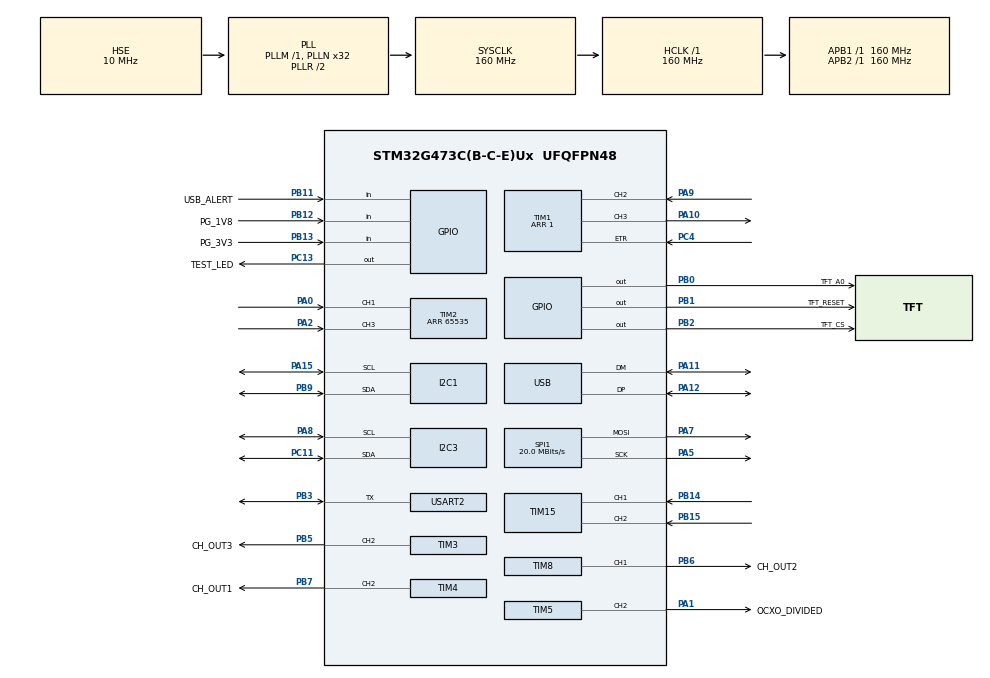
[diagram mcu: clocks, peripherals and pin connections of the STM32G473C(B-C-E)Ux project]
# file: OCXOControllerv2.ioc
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Dma.I2C3_RX.3.Direction=DMA_PERIPH_TO_MEMORY
Dma.I2C3_RX.3.EventEnable=DISABLE
Dma.I2C3_RX.3.Instance=DMA2_Channel1
Dma.I2C3_RX.3.MemDataAlignment=DMA_MDATAALIGN_BYTE
Dma.I2C3_RX.3.MemInc=DMA_MINC_ENABLE
Dma.I2C3_RX.3.Mode=DMA_NORMAL
Dma.I2C3_RX.3.PeriphDataAlignment=DMA_PDATAALIGN_BYTE
Dma.I2C3_RX.3.PeriphInc=DMA_PINC_DISABLE
Dma.I2C3_RX.3.Polarity=HAL_DMAMUX_REQ_GEN_RISING
Dma.I2C3_RX.3.Priority=DMA_PRIORITY_LOW
Dma.I2C3_RX.3.RequestNumber=1
Dma.I2C3_RX.3.SignalID=NONE
Dma.I2C3_RX.3.SyncEnable=DISABLE
Dma.I2C3_RX.3.SyncPolarity=HAL_DMAMUX_SYNC_NO_EVENT
Dma.I2C3_RX.3.SyncRequestNumber=1
Dma.I2C3_RX.3.SyncSignalID=NONE
Dma.I2C3_TX.4.Direction=DMA_MEMORY_TO_PERIPH
Dma.I2C3_TX.4.EventEnable=DISABLE
Dma.I2C3_TX.4.Instance=DMA2_Channel2
Dma.I2C3_TX.4.MemDataAlignment=DMA_MDATAALIGN_BYTE
Dma.I2C3_TX.4.MemInc=DMA_MINC_ENABLE
Dma.I2C3_TX.4.Mode=DMA_NORMAL
Dma.I2C3_TX.4.PeriphDataAlignment=DMA_PDATAALIGN_BYTE
Dma.I2C3_TX.4.PeriphInc=DMA_PINC_DISABLE
Dma.I2C3_TX.4.Polarity=HAL_DMAMUX_REQ_GEN_RISING
Dma.I2C3_TX.4.Priority=DMA_PRIORITY_LOW
Dma.I2C3_TX.4.RequestNumber=1
Dma.I2C3_TX.4.SignalID=NONE
Dma.I2C3_TX.4.SyncEnable=DISABLE
Dma.I2C3_TX.4.SyncPolarity=HAL_DMAMUX_SYNC_NO_EVENT
Dma.I2C3_TX.4.SyncRequestNumber=1
Dma.I2C3_TX.4.SyncSignalID=NONE
Dma.Request0=USART2_RX
Dma.Request1=USART2_TX
Dma.Request2=SPI1_TX
Dma.Request3=I2C3_RX
Dma.Request4=I2C3_TX
Dma.SPI1_TX.2.Direction=DMA_MEMORY_TO_PERIPH
Dma.SPI1_TX.2.EventEnable=DISABLE
Dma.SPI1_TX.2.Instance=DMA1_Channel3
Dma.SPI1_TX.2.MemDataAlignment=DMA_MDATAALIGN_BYTE
Dma.SPI1_TX.2.MemInc=DMA_MINC_ENABLE
Dma.SPI1_TX.2.Mode=DMA_NORMAL
Dma.SPI1_TX.2.PeriphDataAlignment=DMA_PDATAALIGN_BYTE
Dma.SPI1_TX.2.PeriphInc=DMA_PINC_DISABLE
Dma.SPI1_TX.2.Polarity=HAL_DMAMUX_REQ_GEN_RISING
Dma.SPI1_TX.2.Priority=DMA_PRIORITY_VERY_HIGH
Dma.SPI1_TX.2.RequestNumber=1
Dma.SPI1_TX.2.SignalID=NONE
Dma.SPI1_TX.2.SyncEnable=DISABLE
Dma.SPI1_TX.2.SyncPolarity=HAL_DMAMUX_SYNC_NO_EVENT
Dma.SPI1_TX.2.SyncRequestNumber=1
Dma.SPI1_TX.2.SyncSignalID=NONE
Dma.USART2_RX.0.Direction=DMA_PERIPH_TO_MEMORY
Dma.USART2_RX.0.EventEnable=DISABLE
Dma.USART2_RX.0.Instance=DMA1_Channel1
Dma.USART2_RX.0.MemDataAlignment=DMA_MDATAALIGN_BYTE
Dma.USART2_RX.0.MemInc=DMA_MINC_ENABLE
Dma.USART2_RX.0.Mode=DMA_NORMAL
Dma.USART2_RX.0.PeriphDataAlignment=DMA_PDATAALIGN_BYTE
Dma.USART2_RX.0.PeriphInc=DMA_PINC_DISABLE
Dma.USART2_RX.0.Polarity=HAL_DMAMUX_REQ_GEN_RISING
Dma.USART2_RX.0.Priority=DMA_PRIORITY_LOW
Dma.USART2_RX.0.RequestNumber=1
Dma.USART2_RX.0.SignalID=NONE
Dma.USART2_RX.0.SyncEnable=DISABLE
Dma.USART2_RX.0.SyncPolarity=HAL_DMAMUX_SYNC_NO_EVENT
Dma.USART2_RX.0.SyncRequestNumber=1
Dma.USART2_RX.0.SyncSignalID=NONE
Dma.USART2_TX.1.Direction=DMA_MEMORY_TO_PERIPH
Dma.USART2_TX.1.EventEnable=DISABLE
Dma.USART2_TX.1.Instance=DMA1_Channel4
Dma.USART2_TX.1.MemDataAlignment=DMA_MDATAALIGN_BYTE
Dma.USART2_TX.1.MemInc=DMA_MINC_ENABLE
Dma.USART2_TX.1.Mode=DMA_NORMAL
Dma.USART2_TX.1.PeriphDataAlignment=DMA_PDATAALIGN_BYTE
Dma.USART2_TX.1.PeriphInc=DMA_PINC_DISABLE
Dma.USART2_TX.1.Polarity=HAL_DMAMUX_REQ_GEN_RISING
Dma.USART2_TX.1.Priority=DMA_PRIORITY_LOW
Dma.USART2_TX.1.RequestNumber=1
Dma.USART2_TX.1.SignalID=NONE
Dma.USART2_TX.1.SyncEnable=DISABLE
Dma.USART2_TX.1.SyncPolarity=HAL_DMAMUX_SYNC_NO_EVENT
Dma.USART2_TX.1.SyncRequestNumber=1
Dma.USART2_TX.1.SyncSignalID=NONE
I2C1.Speed=100
I2C1.Timing=0x30D29DE4
I2C3.Timing=0x30D29DE4
Mcu.Family=STM32G4
Mcu.Name=STM32G473C(B-C-E)Ux
Mcu.Package=UFQFPN48
NVIC.DMA1_Channel1_IRQn=true\:0\:0\:false\:false\:true\:false\:true\:true
NVIC.DMA1_Channel3_IRQn=true\:0\:0\:false\:false\:true\:false\:true\:true
NVIC.DMA1_Channel4_IRQn=true\:0\:0\:false\:false\:true\:false\:true\:true
NVIC.DMA2_Channel1_IRQn=true\:0\:0\:false\:false\:true\:false\:true\:true
NVIC.DMA2_Channel2_IRQn=true\:0\:0\:false\:false\:true\:false\:true\:true
NVIC.PriorityGroup=NVIC_PRIORITYGROUP_4
NVIC.TIM1_BRK_TIM15_IRQn=true\:0\:0\:false\:false\:true\:true\:true\:true
NVIC.TIM2_IRQn=true\:0\:0\:false\:false\:true\:true\:true\:true
NVIC.TIM6_DAC_IRQn=true\:0\:0\:true\:false\:true\:true\:true\:true
NVIC.TIM7_DAC_IRQn=true\:2\:0\:true\:false\:true\:true\:true\:true
NVIC.USB_LP_IRQn=true\:0\:0\:false\:false\:true\:false\:true\:true
PA0.Signal=S_TIM2_CH1
PA1.GPIO_Label=OCXO_DIVIDED
PA1.GPIO_Speed=GPIO_SPEED_FREQ_VERY_HIGH
PA1.Signal=S_TIM5_CH2
PA10.Signal=S_TIM1_CH3
PA11.Mode=Device
PA11.Signal=USB_DM
PA12.Mode=Device
PA12.Signal=USB_DP
PA13.Mode=Serial_Wire
PA13.Signal=SYS_JTMS-SWDIO
PA14.Mode=Serial_Wire
PA14.Signal=SYS_JTCK-SWCLK
PA15.Mode=I2C
PA15.Signal=I2C1_SCL
PA2.Signal=S_TIM2_CH3
PA5.GPIO_Speed=GPIO_SPEED_FREQ_VERY_HIGH
PA5.Mode=TX_Only_Simplex_Unidirect_Master
PA5.Signal=SPI1_SCK
PA7.GPIO_Speed=GPIO_SPEED_FREQ_VERY_HIGH
PA7.Mode=TX_Only_Simplex_Unidirect_Master
PA7.Signal=SPI1_MOSI
PA8.Mode=I2C
PA8.Signal=I2C3_SCL
PA9.Signal=S_TIM1_CH2
PB0.GPIO_Label=TFT_A0
PB0.Signal=GPIO_Output
PB1.GPIO_Label=TFT_RESET
PB1.Signal=GPIO_Output
PB11.GPIO_Label=USB_ALERT
PB11.Signal=GPIO_Input
PB12.GPIO_Label=PG_1V8
PB12.Signal=GPIO_Input
PB13.GPIO_Label=PG_3V3
PB13.Signal=GPIO_Input
PB14.Signal=S_TIM15_CH1
PB15.Signal=S_TIM15_CH2
PB2.GPIO_Label=TFT_CS
PB2.Signal=GPIO_Output
PB3.Mode=Half_duplex(single_wire_mode)
PB3.Signal=USART2_TX
PB5.GPIO_Label=CH_OUT3
PB5.GPIO_Speed=GPIO_SPEED_FREQ_VERY_HIGH
PB5.Signal=S_TIM3_CH2
PB6.GPIO_Label=CH_OUT2
PB6.GPIO_Speed=GPIO_SPEED_FREQ_VERY_HIGH
PB6.Signal=S_TIM8_CH1
PB7.GPIO_Label=CH_OUT1
PB7.GPIO_Speed=GPIO_SPEED_FREQ_VERY_HIGH
PB7.Signal=S_TIM4_CH2
PB9.Mode=I2C
PB9.Signal=I2C1_SDA
PC11.Mode=I2C
PC11.Signal=I2C3_SDA
PC13.GPIO_Label=TEST_LED
PC13.PinState=GPIO_PIN_RESET
PC13.Signal=GPIO_Output
PC4.Signal=S_TIM1_ETR
PF0-OSC_IN.Mode=HSE-External-Clock-Source
PF0-OSC_IN.Signal=RCC_OSC_IN
ProjectManager.HeapSize=0x200
ProjectManager.StackSize=0x400
ProjectManager.TargetToolchain=STM32CubeIDE
RCC.ADC12Freq_Value=160000000
RCC.ADC345Freq_Value=160000000
RCC.AHBFreq_Value=160000000
RCC.APB1Freq_Value=160000000
RCC.APB1TimFreq_Value=160000000
RCC.APB2Freq_Value=160000000
RCC.APB2TimFreq_Value=160000000
RCC.CK48CLockSelection=RCC_USBCLKSOURCE_HSI48
RCC.CortexFreq_Value=160000000
RCC.EXTERNAL_CLOCK_VALUE=12288000
RCC.HCLKFreq_Value=160000000
RCC.HSE_VALUE=10000000
RCC.HSI48_VALUE=48000000
RCC.HSI_VALUE=16000000
RCC.LSE_VALUE=32768
RCC.PLLN=32
RCC.PLLSourceVirtual=RCC_PLLSOURCE_HSE
RCC.SYSCLKFreq_VALUE=160000000
RCC.SYSCLKSource=RCC_SYSCLKSOURCE_PLLCLK
RCC.USBFreq_Value=48000000
RCC.VCOOutputFreq_Value=320000000
SH.S_TIM15_CH1.0=TIM15_CH1,Input_Capture1_from_TI1
SH.S_TIM15_CH2.0=TIM15_CH2,Input_Capture2_from_TI2
SH.S_TIM1_CH2.0=TIM1_CH2,TriggerSource_TI2FP2
SH.S_TIM1_CH3.0=TIM1_CH3,PWM Generation3 CH3
SH.S_TIM1_ETR.0=TIM1_ETR,ClockSourceETR_Mode2
SH.S_TIM2_CH1.0=TIM2_CH1,Input_Capture1_from_TI1
SH.S_TIM2_CH3.0=TIM2_CH3,Input_Capture3_from_TI3
SH.S_TIM3_CH2.0=TIM3_CH2,PWM Generation2 CH2
SH.S_TIM4_CH2.0=TIM4_CH2,PWM Generation2 CH2
SH.S_TIM5_CH2.0=TIM5_CH2,PWM Generation2 CH2
SH.S_TIM8_CH1.0=TIM8_CH1,PWM Generation1 CH1
SPI1.BaudRatePrescaler=SPI_BAUDRATEPRESCALER_8
SPI1.CalculateBaudRate=20.0 MBits/s
SPI1.DataSize=SPI_DATASIZE_8BIT
SPI1.Direction=SPI_DIRECTION_2LINES
SPI1.Mode=SPI_MODE_MASTER
SPI1.VirtualType=VM_MASTER
TIM1.Channel-PWM\ Generation3\ CH3=TIM_CHANNEL_3
TIM1.PeriodNoDither=1
TIM1.PulseNoDither_3=1
TIM1.TIM_MasterOutputTrigger=TIM_TRGO_UPDATE
TIM1.TIM_MasterSlaveMode=TIM_MASTERSLAVEMODE_DISABLE
TIM15.Channel-Input_Capture1_from_TI1=TIM_CHANNEL_1
TIM15.Channel-Input_Capture2_from_TI2=TIM_CHANNEL_2
TIM15.ICPolarity_CH2=TIM_INPUTCHANNELPOLARITY_FALLING
TIM2.Channel-Input_Capture1_from_TI1=TIM_CHANNEL_1
TIM2.Channel-Input_Capture3_from_TI3=TIM_CHANNEL_3
TIM2.ICPolarity_CH3=TIM_INPUTCHANNELPOLARITY_FALLING
TIM2.PeriodNoDither=65535
TIM3.AutoReloadPreload=TIM_AUTORELOAD_PRELOAD_DISABLE
TIM3.Channel-PWM\ Generation2\ CH2=TIM_CHANNEL_2
TIM3.TIM_MasterOutputTrigger=TIM_TRGO_RESET
TIM3.TIM_MasterSlaveMode=TIM_MASTERSLAVEMODE_DISABLE
TIM4.Channel-PWM\ Generation2\ CH2=TIM_CHANNEL_2
TIM5.Channel-PWM\ Generation2\ CH2=TIM_CHANNEL_2
TIM5.PeriodNoDither=4999
TIM5.Prescaler=999
TIM5.PulseNoDither_2=2500
TIM5.TIM_MasterOutputTrigger=TIM_TRGO_OC2REF
TIM5.TIM_MasterSlaveMode=TIM_MASTERSLAVEMODE_DISABLE
TIM6.PeriodNoDither=999
TIM6.Prescaler=16999
TIM7.PeriodNoDither=1999
TIM7.Prescaler=16999
TIM8.Channel-PWM\ Generation1\ CH1=TIM_CHANNEL_1
USART2.BaudRate=9600
USART2.VirtualMode-Half_duplex(single_wire_mode)=VM_ASYNC
USB_DEVICE.CLASS_NAME_FS=CDC
USB_DEVICE.VirtualMode=Cdc
USB_DEVICE.VirtualModeFS=Cdc_FS
VP_CORDIC_VS_CORDIC.Mode=CORDIC_Activate
VP_SYS_VS_DBSignals.Mode=DisableDeadBatterySignals
VP_TIM15_VS_ClockSourceINT.Mode=Internal
VP_TIM15_VS_ClockSourceITR.Mode=TriggerSource_ITR4
VP_TIM15_VS_ControllerModeTrigger.Mode=Trigger Mode
VP_TIM1_VS_ControllerModeTrigger.Mode=Trigger Mode
VP_TIM2_VS_ClockSourceINT.Mode=Internal
VP_TIM2_VS_ClockSourceITR.Mode=TriggerSource_ITR4
VP_TIM2_VS_ControllerModeTrigger.Mode=Trigger Mode
VP_TIM3_VS_ClockSourceITR.Mode=TriggerSource_ITR0
VP_TIM3_VS_ControllerModeClock.Mode=Clock Mode
VP_TIM4_VS_ClockSourceITR.Mode=TriggerSource_ITR0
VP_TIM4_VS_ControllerModeClock.Mode=Clock Mode
VP_TIM5_VS_ClockSourceITR.Mode=TriggerSource_ITR0
VP_TIM5_VS_ControllerModeClock.Mode=Clock Mode
VP_TIM6_VS_ClockSourceINT.Mode=Enable_Timer
VP_TIM7_VS_ClockSourceINT.Mode=Enable_Timer
VP_TIM8_VS_ClockSourceITR.Mode=TriggerSource_ITR0
VP_TIM8_VS_ControllerModeClock.Mode=Clock Mode
VP_USB_DEVICE_VS_USB_DEVICE_CDC_FS.Mode=CDC_FS
board=custom

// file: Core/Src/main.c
/* USER CODE BEGIN Header */
/**
  ******************************************************************************
  * @file           : main.c
  * @brief          : Main program body
  ******************************************************************************
  * @attention
  *
  * Copyright (c) 2025 STMicroelectronics.
  * All rights reserved.
  *
  * This software is licensed under terms that can be found in the LICENSE file
  * in the root directory of this software component.
  * If no LICENSE file comes with this software, it is provided AS-IS.
  *
  ******************************************************************************
  */
/* USER CODE END Header */
#include "main.h"
#include "usb_device.h"

CORDIC_HandleTypeDef hcordic;

I2C_HandleTypeDef hi2c1;
I2C_HandleTypeDef hi2c3;
DMA_HandleTypeDef hdma_i2c3_rx;
DMA_HandleTypeDef hdma_i2c3_tx;

SPI_HandleTypeDef hspi1;
DMA_HandleTypeDef hdma_spi1_tx;

TIM_HandleTypeDef htim1;
TIM_HandleTypeDef htim2;
TIM_HandleTypeDef htim3;
TIM_HandleTypeDef htim4;
TIM_HandleTypeDef htim5;
TIM_HandleTypeDef htim6;
TIM_HandleTypeDef htim7;
TIM_HandleTypeDef htim8;
TIM_HandleTypeDef htim15;

UART_HandleTypeDef huart2;
DMA_HandleTypeDef hdma_usart2_rx;
DMA_HandleTypeDef hdma_usart2_tx;

void SystemClock_Config(void);
static void MX_GPIO_Init(void);
static void MX_DMA_Init(void);
static void MX_I2C1_Init(void);
static void MX_SPI1_Init(void);
static void MX_TIM2_Init(void);
static void MX_TIM3_Init(void);
static void MX_I2C3_Init(void);
static void MX_TIM1_Init(void);
static void MX_TIM4_Init(void);
static void MX_TIM5_Init(void);
static void MX_TIM8_Init(void);
static void MX_TIM15_Init(void);
static void MX_USART2_UART_Init(void);
static void MX_CORDIC_Init(void);
static void MX_TIM6_Init(void);
static void MX_TIM7_Init(void);

int main(void)
{

  /* MCU Configuration--------------------------------------------------------*/

  /* Reset of all peripherals, Initializes the Flash interface and the Systick. */
  HAL_Init();

  /* Configure the system clock */
  SystemClock_Config();

  /* Initialize all configured peripherals */
  MX_GPIO_Init();
  MX_DMA_Init();
  MX_I2C1_Init();
  MX_SPI1_Init();
  MX_TIM2_Init();
  MX_TIM3_Init();
  MX_USB_Device_Init();
  MX_I2C3_Init();
  MX_TIM1_Init();
  MX_TIM4_Init();
  MX_TIM5_Init();
  MX_TIM8_Init();
  MX_TIM15_Init();
  MX_USART2_UART_Init();
  MX_CORDIC_Init();
  MX_TIM6_Init();
  MX_TIM7_Init();
  /* USER CODE BEGIN 2 */
  initMain(&hi2c1, &hi2c3, &hspi1, &hdma_spi1_tx, &htim1, &htim2, &htim3, &htim4, &htim5, &htim6,
           &htim7, &htim8, &htim15, &huart2, &hdma_usart2_rx, &hdma_usart2_tx, &hcordic);
  /* USER CODE END 2 */

  /* Infinite loop */
  while (1)
  {

    /* USER CODE BEGIN 3 */
    loopMain();
  }
  /* USER CODE END 3 */
}

void SystemClock_Config(void)
{
  RCC_OscInitTypeDef RCC_OscInitStruct = {0};
  RCC_ClkInitTypeDef RCC_ClkInitStruct = {0};

  /** Configure the main internal regulator output voltage
  */
  HAL_PWREx_ControlVoltageScaling(PWR_REGULATOR_VOLTAGE_SCALE1_BOOST);

  /** Initializes the RCC Oscillators according to the specified parameters
  * in the RCC_OscInitTypeDef structure.
  */
  RCC_OscInitStruct.OscillatorType = RCC_OSCILLATORTYPE_HSI48|RCC_OSCILLATORTYPE_HSE;
  RCC_OscInitStruct.HSEState = RCC_HSE_BYPASS;
  RCC_OscInitStruct.HSI48State = RCC_HSI48_ON;
  RCC_OscInitStruct.PLL.PLLState = RCC_PLL_ON;
  RCC_OscInitStruct.PLL.PLLSource = RCC_PLLSOURCE_HSE;
  RCC_OscInitStruct.PLL.PLLM = RCC_PLLM_DIV1;
  RCC_OscInitStruct.PLL.PLLN = 32;
  RCC_OscInitStruct.PLL.PLLP = RCC_PLLP_DIV2;
  RCC_OscInitStruct.PLL.PLLQ = RCC_PLLQ_DIV2;
  RCC_OscInitStruct.PLL.PLLR = RCC_PLLR_DIV2;
  if (HAL_RCC_OscConfig(&RCC_OscInitStruct) != HAL_OK)
  {
    Error_Handler();
  }

  /** Initializes the CPU, AHB and APB buses clocks
  */
  RCC_ClkInitStruct.ClockType = RCC_CLOCKTYPE_HCLK|RCC_CLOCKTYPE_SYSCLK
                              |RCC_CLOCKTYPE_PCLK1|RCC_CLOCKTYPE_PCLK2;
  RCC_ClkInitStruct.SYSCLKSource = RCC_SYSCLKSOURCE_PLLCLK;
  RCC_ClkInitStruct.AHBCLKDivider = RCC_SYSCLK_DIV1;
  RCC_ClkInitStruct.APB1CLKDivider = RCC_HCLK_DIV1;
  RCC_ClkInitStruct.APB2CLKDivider = RCC_HCLK_DIV1;

  if (HAL_RCC_ClockConfig(&RCC_ClkInitStruct, FLASH_LATENCY_4) != HAL_OK)
  {
    Error_Handler();
  }
}

static void MX_CORDIC_Init(void)
{

  hcordic.Instance = CORDIC;
  if (HAL_CORDIC_Init(&hcordic) != HAL_OK)
  {
    Error_Handler();
  }

}

static void MX_I2C1_Init(void)
{

  hi2c1.Instance = I2C1;
  hi2c1.Init.Timing = 0x30D29DE4;
  hi2c1.Init.OwnAddress1 = 0;
  hi2c1.Init.AddressingMode = I2C_ADDRESSINGMODE_7BIT;
  hi2c1.Init.DualAddressMode = I2C_DUALADDRESS_DISABLE;
  hi2c1.Init.OwnAddress2 = 0;
  hi2c1.Init.OwnAddress2Masks = I2C_OA2_NOMASK;
  hi2c1.Init.GeneralCallMode = I2C_GENERALCALL_DISABLE;
  hi2c1.Init.NoStretchMode = I2C_NOSTRETCH_DISABLE;
  if (HAL_I2C_Init(&hi2c1) != HAL_OK)
  {
    Error_Handler();
  }

  /** Configure Analogue filter
  */
  if (HAL_I2CEx_ConfigAnalogFilter(&hi2c1, I2C_ANALOGFILTER_ENABLE) != HAL_OK)
  {
    Error_Handler();
  }

  /** Configure Digital filter
  */
  if (HAL_I2CEx_ConfigDigitalFilter(&hi2c1, 0) != HAL_OK)
  {
    Error_Handler();
  }

}

static void MX_I2C3_Init(void)
{

  hi2c3.Instance = I2C3;
  hi2c3.Init.Timing = 0x30D29DE4;
  hi2c3.Init.OwnAddress1 = 0;
  hi2c3.Init.AddressingMode = I2C_ADDRESSINGMODE_7BIT;
  hi2c3.Init.DualAddressMode = I2C_DUALADDRESS_DISABLE;
  hi2c3.Init.OwnAddress2 = 0;
  hi2c3.Init.OwnAddress2Masks = I2C_OA2_NOMASK;
  hi2c3.Init.GeneralCallMode = I2C_GENERALCALL_DISABLE;
  hi2c3.Init.NoStretchMode = I2C_NOSTRETCH_DISABLE;
  if (HAL_I2C_Init(&hi2c3) != HAL_OK)
  {
    Error_Handler();
  }

  /** Configure Analogue filter
  */
  if (HAL_I2CEx_ConfigAnalogFilter(&hi2c3, I2C_ANALOGFILTER_ENABLE) != HAL_OK)
  {
    Error_Handler();
  }

  /** Configure Digital filter
  */
  if (HAL_I2CEx_ConfigDigitalFilter(&hi2c3, 0) != HAL_OK)
  {
    Error_Handler();
  }

}

static void MX_SPI1_Init(void)
{

  /* SPI1 parameter configuration*/
  hspi1.Instance = SPI1;
  hspi1.Init.Mode = SPI_MODE_MASTER;
  hspi1.Init.Direction = SPI_DIRECTION_2LINES;
  hspi1.Init.DataSize = SPI_DATASIZE_8BIT;
  hspi1.Init.CLKPolarity = SPI_POLARITY_LOW;
  hspi1.Init.CLKPhase = SPI_PHASE_1EDGE;
  hspi1.Init.NSS = SPI_NSS_SOFT;
  hspi1.Init.BaudRatePrescaler = SPI_BAUDRATEPRESCALER_8;
  hspi1.Init.FirstBit = SPI_FIRSTBIT_MSB;
  hspi1.Init.TIMode = SPI_TIMODE_DISABLE;
  hspi1.Init.CRCCalculation = SPI_CRCCALCULATION_DISABLE;
  hspi1.Init.CRCPolynomial = 7;
  hspi1.Init.CRCLength = SPI_CRC_LENGTH_DATASIZE;
  hspi1.Init.NSSPMode = SPI_NSS_PULSE_ENABLE;
  if (HAL_SPI_Init(&hspi1) != HAL_OK)
  {
    Error_Handler();
  }

}

static void MX_TIM1_Init(void)
{

  TIM_ClockConfigTypeDef sClockSourceConfig = {0};
  TIM_SlaveConfigTypeDef sSlaveConfig = {0};
  TIM_MasterConfigTypeDef sMasterConfig = {0};
  TIM_OC_InitTypeDef sConfigOC = {0};
  TIM_BreakDeadTimeConfigTypeDef sBreakDeadTimeConfig = {0};

  htim1.Instance = TIM1;
  htim1.Init.Prescaler = 0;
  htim1.Init.CounterMode = TIM_COUNTERMODE_UP;
  htim1.Init.Period = 1;
  htim1.Init.ClockDivision = TIM_CLOCKDIVISION_DIV1;
  htim1.Init.RepetitionCounter = 0;
  htim1.Init.AutoReloadPreload = TIM_AUTORELOAD_PRELOAD_DISABLE;
  if (HAL_TIM_Base_Init(&htim1) != HAL_OK)
  {
    Error_Handler();
  }
  sClockSourceConfig.ClockSource = TIM_CLOCKSOURCE_ETRMODE2;
  sClockSourceConfig.ClockPolarity = TIM_CLOCKPOLARITY_NONINVERTED;
  sClockSourceConfig.ClockPrescaler = TIM_CLOCKPRESCALER_DIV1;
  sClockSourceConfig.ClockFilter = 0;
  if (HAL_TIM_ConfigClockSource(&htim1, &sClockSourceConfig) != HAL_OK)
  {
    Error_Handler();
  }
  if (HAL_TIM_PWM_Init(&htim1) != HAL_OK)
  {
    Error_Handler();
  }
  sSlaveConfig.SlaveMode = TIM_SLAVEMODE_TRIGGER;
  sSlaveConfig.InputTrigger = TIM_TS_TI2FP2;
  sSlaveConfig.TriggerPolarity = TIM_TRIGGERPOLARITY_RISING;
  sSlaveConfig.TriggerFilter = 0;
  if (HAL_TIM_SlaveConfigSynchro(&htim1, &sSlaveConfig) != HAL_OK)
  {
    Error_Handler();
  }
  sMasterConfig.MasterOutputTrigger = TIM_TRGO_UPDATE;
  sMasterConfig.MasterOutputTrigger2 = TIM_TRGO2_RESET;
  sMasterConfig.MasterSlaveMode = TIM_MASTERSLAVEMODE_DISABLE;
  if (HAL_TIMEx_MasterConfigSynchronization(&htim1, &sMasterConfig) != HAL_OK)
  {
    Error_Handler();
  }
  sConfigOC.OCMode = TIM_OCMODE_PWM1;
  sConfigOC.Pulse = 1;
  sConfigOC.OCPolarity = TIM_OCPOLARITY_HIGH;
  sConfigOC.OCNPolarity = TIM_OCNPOLARITY_HIGH;
  sConfigOC.OCFastMode = TIM_OCFAST_DISABLE;
  sConfigOC.OCIdleState = TIM_OCIDLESTATE_RESET;
  sConfigOC.OCNIdleState = TIM_OCNIDLESTATE_RESET;
  if (HAL_TIM_PWM_ConfigChannel(&htim1, &sConfigOC, TIM_CHANNEL_3) != HAL_OK)
  {
    Error_Handler();
  }
  sBreakDeadTimeConfig.OffStateRunMode = TIM_OSSR_DISABLE;
  sBreakDeadTimeConfig.OffStateIDLEMode = TIM_OSSI_DISABLE;
  sBreakDeadTimeConfig.LockLevel = TIM_LOCKLEVEL_OFF;
  sBreakDeadTimeConfig.DeadTime = 0;
  sBreakDeadTimeConfig.BreakState = TIM_BREAK_DISABLE;
  sBreakDeadTimeConfig.BreakPolarity = TIM_BREAKPOLARITY_HIGH;
  sBreakDeadTimeConfig.BreakFilter = 0;
  sBreakDeadTimeConfig.BreakAFMode = TIM_BREAK_AFMODE_INPUT;
  sBreakDeadTimeConfig.Break2State = TIM_BREAK2_DISABLE;
  sBreakDeadTimeConfig.Break2Polarity = TIM_BREAK2POLARITY_HIGH;
  sBreakDeadTimeConfig.Break2Filter = 0;
  sBreakDeadTimeConfig.Break2AFMode = TIM_BREAK_AFMODE_INPUT;
  sBreakDeadTimeConfig.AutomaticOutput = TIM_AUTOMATICOUTPUT_DISABLE;
  if (HAL_TIMEx_ConfigBreakDeadTime(&htim1, &sBreakDeadTimeConfig) != HAL_OK)
  {
    Error_Handler();
  }
  HAL_TIM_MspPostInit(&htim1);

}

static void MX_TIM2_Init(void)
{

  TIM_ClockConfigTypeDef sClockSourceConfig = {0};
  TIM_SlaveConfigTypeDef sSlaveConfig = {0};
  TIM_MasterConfigTypeDef sMasterConfig = {0};
  TIM_IC_InitTypeDef sConfigIC = {0};

  htim2.Instance = TIM2;
  htim2.Init.Prescaler = 0;
  htim2.Init.CounterMode = TIM_COUNTERMODE_UP;
  htim2.Init.Period = 65535;
  htim2.Init.ClockDivision = TIM_CLOCKDIVISION_DIV1;
  htim2.Init.AutoReloadPreload = TIM_AUTORELOAD_PRELOAD_DISABLE;
  if (HAL_TIM_Base_Init(&htim2) != HAL_OK)
  {
    Error_Handler();
  }
  sClockSourceConfig.ClockSource = TIM_CLOCKSOURCE_INTERNAL;
  if (HAL_TIM_ConfigClockSource(&htim2, &sClockSourceConfig) != HAL_OK)
  {
    Error_Handler();
  }
  if (HAL_TIM_IC_Init(&htim2) != HAL_OK)
  {
    Error_Handler();
  }
  sSlaveConfig.SlaveMode = TIM_SLAVEMODE_TRIGGER;
  sSlaveConfig.InputTrigger = TIM_TS_ITR4;
  if (HAL_TIM_SlaveConfigSynchro(&htim2, &sSlaveConfig) != HAL_OK)
  {
    Error_Handler();
  }
  sMasterConfig.MasterOutputTrigger = TIM_TRGO_RESET;
  sMasterConfig.MasterSlaveMode = TIM_MASTERSLAVEMODE_DISABLE;
  if (HAL_TIMEx_MasterConfigSynchronization(&htim2, &sMasterConfig) != HAL_OK)
  {
    Error_Handler();
  }
  sConfigIC.ICPolarity = TIM_INPUTCHANNELPOLARITY_RISING;
  sConfigIC.ICSelection = TIM_ICSELECTION_DIRECTTI;
  sConfigIC.ICPrescaler = TIM_ICPSC_DIV1;
  sConfigIC.ICFilter = 0;
  if (HAL_TIM_IC_ConfigChannel(&htim2, &sConfigIC, TIM_CHANNEL_1) != HAL_OK)
  {
    Error_Handler();
  }
  sConfigIC.ICPolarity = TIM_INPUTCHANNELPOLARITY_FALLING;
  if (HAL_TIM_IC_ConfigChannel(&htim2, &sConfigIC, TIM_CHANNEL_3) != HAL_OK)
  {
    Error_Handler();
  }

}

static void MX_TIM3_Init(void)
{

  TIM_SlaveConfigTypeDef sSlaveConfig = {0};
  TIM_MasterConfigTypeDef sMasterConfig = {0};
  TIM_OC_InitTypeDef sConfigOC = {0};

  htim3.Instance = TIM3;
  htim3.Init.Prescaler = 0;
  htim3.Init.CounterMode = TIM_COUNTERMODE_UP;
  htim3.Init.Period = 65535;
  htim3.Init.ClockDivision = TIM_CLOCKDIVISION_DIV1;
  htim3.Init.AutoReloadPreload = TIM_AUTORELOAD_PRELOAD_DISABLE;
  if (HAL_TIM_Base_Init(&htim3) != HAL_OK)
  {
    Error_Handler();
  }
  if (HAL_TIM_PWM_Init(&htim3) != HAL_OK)
  {
    Error_Handler();
  }
  sSlaveConfig.SlaveMode = TIM_SLAVEMODE_EXTERNAL1;
  sSlaveConfig.InputTrigger = TIM_TS_ITR0;
  if (HAL_TIM_SlaveConfigSynchro(&htim3, &sSlaveConfig) != HAL_OK)
  {
    Error_Handler();
  }
  sMasterConfig.MasterOutputTrigger = TIM_TRGO_RESET;
  sMasterConfig.MasterSlaveMode = TIM_MASTERSLAVEMODE_DISABLE;
  if (HAL_TIMEx_MasterConfigSynchronization(&htim3, &sMasterConfig) != HAL_OK)
  {
    Error_Handler();
  }
  sConfigOC.OCMode = TIM_OCMODE_PWM1;
  sConfigOC.Pulse = 0;
  sConfigOC.OCPolarity = TIM_OCPOLARITY_HIGH;
  sConfigOC.OCFastMode = TIM_OCFAST_DISABLE;
  if (HAL_TIM_PWM_ConfigChannel(&htim3, &sConfigOC, TIM_CHANNEL_2) != HAL_OK)
  {
    Error_Handler();
  }
  HAL_TIM_MspPostInit(&htim3);

}

static void MX_TIM4_Init(void)
{

  TIM_SlaveConfigTypeDef sSlaveConfig = {0};
  TIM_MasterConfigTypeDef sMasterConfig = {0};
  TIM_OC_InitTypeDef sConfigOC = {0};

  htim4.Instance = TIM4;
  htim4.Init.Prescaler = 0;
  htim4.Init.CounterMode = TIM_COUNTERMODE_UP;
  htim4.Init.Period = 65535;
  htim4.Init.ClockDivision = TIM_CLOCKDIVISION_DIV1;
  htim4.Init.AutoReloadPreload = TIM_AUTORELOAD_PRELOAD_DISABLE;
  if (HAL_TIM_Base_Init(&htim4) != HAL_OK)
  {
    Error_Handler();
  }
  if (HAL_TIM_PWM_Init(&htim4) != HAL_OK)
  {
    Error_Handler();
  }
  sSlaveConfig.SlaveMode = TIM_SLAVEMODE_EXTERNAL1;
  sSlaveConfig.InputTrigger = TIM_TS_ITR0;
  if (HAL_TIM_SlaveConfigSynchro(&htim4, &sSlaveConfig) != HAL_OK)
  {
    Error_Handler();
  }
  sMasterConfig.MasterOutputTrigger = TIM_TRGO_RESET;
  sMasterConfig.MasterSlaveMode = TIM_MASTERSLAVEMODE_DISABLE;
  if (HAL_TIMEx_MasterConfigSynchronization(&htim4, &sMasterConfig) != HAL_OK)
  {
    Error_Handler();
  }
  sConfigOC.OCMode = TIM_OCMODE_PWM1;
  sConfigOC.Pulse = 0;
  sConfigOC.OCPolarity = TIM_OCPOLARITY_HIGH;
  sConfigOC.OCFastMode = TIM_OCFAST_DISABLE;
  if (HAL_TIM_PWM_ConfigChannel(&htim4, &sConfigOC, TIM_CHANNEL_2) != HAL_OK)
  {
    Error_Handler();
  }
  HAL_TIM_MspPostInit(&htim4);

}

static void MX_TIM5_Init(void)
{

  TIM_SlaveConfigTypeDef sSlaveConfig = {0};
  TIM_MasterConfigTypeDef sMasterConfig = {0};
  TIM_OC_InitTypeDef sConfigOC = {0};

  htim5.Instance = TIM5;
  htim5.Init.Prescaler = 999;
  htim5.Init.CounterMode = TIM_COUNTERMODE_UP;
  htim5.Init.Period = 4999;
  htim5.Init.ClockDivision = TIM_CLOCKDIVISION_DIV1;
  htim5.Init.AutoReloadPreload = TIM_AUTORELOAD_PRELOAD_DISABLE;
  if (HAL_TIM_Base_Init(&htim5) != HAL_OK)
  {
    Error_Handler();
  }
  if (HAL_TIM_PWM_Init(&htim5) != HAL_OK)
  {
    Error_Handler();
  }
  sSlaveConfig.SlaveMode = TIM_SLAVEMODE_EXTERNAL1;
  sSlaveConfig.InputTrigger = TIM_TS_ITR0;
  if (HAL_TIM_SlaveConfigSynchro(&htim5, &sSlaveConfig) != HAL_OK)
  {
    Error_Handler();
  }
  sMasterConfig.MasterOutputTrigger = TIM_TRGO_OC2REF;
  sMasterConfig.MasterSlaveMode = TIM_MASTERSLAVEMODE_DISABLE;
  if (HAL_TIMEx_MasterConfigSynchronization(&htim5, &sMasterConfig) != HAL_OK)
  {
    Error_Handler();
  }
  sConfigOC.OCMode = TIM_OCMODE_PWM1;
  sConfigOC.Pulse = 2500;
  sConfigOC.OCPolarity = TIM_OCPOLARITY_HIGH;
  sConfigOC.OCFastMode = TIM_OCFAST_DISABLE;
  if (HAL_TIM_PWM_ConfigChannel(&htim5, &sConfigOC, TIM_CHANNEL_2) != HAL_OK)
  {
    Error_Handler();
  }
  HAL_TIM_MspPostInit(&htim5);

}

static void MX_TIM6_Init(void)
{

  TIM_MasterConfigTypeDef sMasterConfig = {0};

  htim6.Instance = TIM6;
  htim6.Init.Prescaler = 16999;
  htim6.Init.CounterMode = TIM_COUNTERMODE_UP;
  htim6.Init.Period = 999;
  htim6.Init.AutoReloadPreload = TIM_AUTORELOAD_PRELOAD_DISABLE;
  if (HAL_TIM_Base_Init(&htim6) != HAL_OK)
  {
    Error_Handler();
  }
  sMasterConfig.MasterOutputTrigger = TIM_TRGO_RESET;
  sMasterConfig.MasterSlaveMode = TIM_MASTERSLAVEMODE_DISABLE;
  if (HAL_TIMEx_MasterConfigSynchronization(&htim6, &sMasterConfig) != HAL_OK)
  {
    Error_Handler();
  }

}

static void MX_TIM7_Init(void)
{

  TIM_MasterConfigTypeDef sMasterConfig = {0};

  htim7.Instance = TIM7;
  htim7.Init.Prescaler = 16999;
  htim7.Init.CounterMode = TIM_COUNTERMODE_UP;
  htim7.Init.Period = 1999;
  htim7.Init.AutoReloadPreload = TIM_AUTORELOAD_PRELOAD_DISABLE;
  if (HAL_TIM_Base_Init(&htim7) != HAL_OK)
  {
    Error_Handler();
  }
  sMasterConfig.MasterOutputTrigger = TIM_TRGO_RESET;
  sMasterConfig.MasterSlaveMode = TIM_MASTERSLAVEMODE_DISABLE;
  if (HAL_TIMEx_MasterConfigSynchronization(&htim7, &sMasterConfig) != HAL_OK)
  {
    Error_Handler();
  }

}

static void MX_TIM8_Init(void)
{

  TIM_SlaveConfigTypeDef sSlaveConfig = {0};
  TIM_MasterConfigTypeDef sMasterConfig = {0};
  TIM_OC_InitTypeDef sConfigOC = {0};
  TIM_BreakDeadTimeConfigTypeDef sBreakDeadTimeConfig = {0};

  htim8.Instance = TIM8;
  htim8.Init.Prescaler = 0;
  htim8.Init.CounterMode = TIM_COUNTERMODE_UP;
  htim8.Init.Period = 65535;
  htim8.Init.ClockDivision = TIM_CLOCKDIVISION_DIV1;
  htim8.Init.RepetitionCounter = 0;
  htim8.Init.AutoReloadPreload = TIM_AUTORELOAD_PRELOAD_DISABLE;
  if (HAL_TIM_Base_Init(&htim8) != HAL_OK)
  {
    Error_Handler();
  }
  if (HAL_TIM_PWM_Init(&htim8) != HAL_OK)
  {
    Error_Handler();
  }
  sSlaveConfig.SlaveMode = TIM_SLAVEMODE_EXTERNAL1;
  sSlaveConfig.InputTrigger = TIM_TS_ITR0;
  if (HAL_TIM_SlaveConfigSynchro(&htim8, &sSlaveConfig) != HAL_OK)
  {
    Error_Handler();
  }
  sMasterConfig.MasterOutputTrigger = TIM_TRGO_RESET;
  sMasterConfig.MasterOutputTrigger2 = TIM_TRGO2_RESET;
  sMasterConfig.MasterSlaveMode = TIM_MASTERSLAVEMODE_DISABLE;
  if (HAL_TIMEx_MasterConfigSynchronization(&htim8, &sMasterConfig) != HAL_OK)
  {
    Error_Handler();
  }
  sConfigOC.OCMode = TIM_OCMODE_PWM1;
  sConfigOC.Pulse = 0;
  sConfigOC.OCPolarity = TIM_OCPOLARITY_HIGH;
  sConfigOC.OCNPolarity = TIM_OCNPOLARITY_HIGH;
  sConfigOC.OCFastMode = TIM_OCFAST_DISABLE;
  sConfigOC.OCIdleState = TIM_OCIDLESTATE_RESET;
  sConfigOC.OCNIdleState = TIM_OCNIDLESTATE_RESET;
  if (HAL_TIM_PWM_ConfigChannel(&htim8, &sConfigOC, TIM_CHANNEL_1) != HAL_OK)
  {
    Error_Handler();
  }
  sBreakDeadTimeConfig.OffStateRunMode = TIM_OSSR_DISABLE;
  sBreakDeadTimeConfig.OffStateIDLEMode = TIM_OSSI_DISABLE;
  sBreakDeadTimeConfig.LockLevel = TIM_LOCKLEVEL_OFF;
  sBreakDeadTimeConfig.DeadTime = 0;
  sBreakDeadTimeConfig.BreakState = TIM_BREAK_DISABLE;
  sBreakDeadTimeConfig.BreakPolarity = TIM_BREAKPOLARITY_HIGH;
  sBreakDeadTimeConfig.BreakFilter = 0;
  sBreakDeadTimeConfig.BreakAFMode = TIM_BREAK_AFMODE_INPUT;
  sBreakDeadTimeConfig.Break2State = TIM_BREAK2_DISABLE;
  sBreakDeadTimeConfig.Break2Polarity = TIM_BREAK2POLARITY_HIGH;
  sBreakDeadTimeConfig.Break2Filter = 0;
  sBreakDeadTimeConfig.Break2AFMode = TIM_BREAK_AFMODE_INPUT;
  sBreakDeadTimeConfig.AutomaticOutput = TIM_AUTOMATICOUTPUT_DISABLE;
  if (HAL_TIMEx_ConfigBreakDeadTime(&htim8, &sBreakDeadTimeConfig) != HAL_OK)
  {
    Error_Handler();
  }
  HAL_TIM_MspPostInit(&htim8);

}

static void MX_TIM15_Init(void)
{

  TIM_ClockConfigTypeDef sClockSourceConfig = {0};
  TIM_SlaveConfigTypeDef sSlaveConfig = {0};
  TIM_MasterConfigTypeDef sMasterConfig = {0};
  TIM_IC_InitTypeDef sConfigIC = {0};

  htim15.Instance = TIM15;
  htim15.Init.Prescaler = 0;
  htim15.Init.CounterMode = TIM_COUNTERMODE_UP;
  htim15.Init.Period = 65535;
  htim15.Init.ClockDivision = TIM_CLOCKDIVISION_DIV1;
  htim15.Init.RepetitionCounter = 0;
  htim15.Init.AutoReloadPreload = TIM_AUTORELOAD_PRELOAD_DISABLE;
  if (HAL_TIM_Base_Init(&htim15) != HAL_OK)
  {
    Error_Handler();
  }
  sClockSourceConfig.ClockSource = TIM_CLOCKSOURCE_INTERNAL;
  if (HAL_TIM_ConfigClockSource(&htim15, &sClockSourceConfig) != HAL_OK)
  {
    Error_Handler();
  }
  if (HAL_TIM_IC_Init(&htim15) != HAL_OK)
  {
    Error_Handler();
  }
  sSlaveConfig.SlaveMode = TIM_SLAVEMODE_TRIGGER;
  sSlaveConfig.InputTrigger = TIM_TS_ITR4;
  if (HAL_TIM_SlaveConfigSynchro(&htim15, &sSlaveConfig) != HAL_OK)
  {
    Error_Handler();
  }
  sMasterConfig.MasterOutputTrigger = TIM_TRGO_RESET;
  sMasterConfig.MasterSlaveMode = TIM_MASTERSLAVEMODE_DISABLE;
  if (HAL_TIMEx_MasterConfigSynchronization(&htim15, &sMasterConfig) != HAL_OK)
  {
    Error_Handler();
  }
  sConfigIC.ICPolarity = TIM_INPUTCHANNELPOLARITY_RISING;
  sConfigIC.ICSelection = TIM_ICSELECTION_DIRECTTI;
  sConfigIC.ICPrescaler = TIM_ICPSC_DIV1;
  sConfigIC.ICFilter = 0;
  if (HAL_TIM_IC_ConfigChannel(&htim15, &sConfigIC, TIM_CHANNEL_1) != HAL_OK)
  {
    Error_Handler();
  }
  sConfigIC.ICPolarity = TIM_INPUTCHANNELPOLARITY_FALLING;
  if (HAL_TIM_IC_ConfigChannel(&htim15, &sConfigIC, TIM_CHANNEL_2) != HAL_OK)
  {
    Error_Handler();
  }

}

static void MX_USART2_UART_Init(void)
{

  huart2.Instance = USART2;
  huart2.Init.BaudRate = 9600;
  huart2.Init.WordLength = UART_WORDLENGTH_8B;
  huart2.Init.StopBits = UART_STOPBITS_1;
  huart2.Init.Parity = UART_PARITY_NONE;
  huart2.Init.Mode = UART_MODE_TX_RX;
  huart2.Init.HwFlowCtl = UART_HWCONTROL_NONE;
  huart2.Init.OverSampling = UART_OVERSAMPLING_16;
  huart2.Init.OneBitSampling = UART_ONE_BIT_SAMPLE_DISABLE;
  huart2.Init.ClockPrescaler = UART_PRESCALER_DIV1;
  huart2.AdvancedInit.AdvFeatureInit = UART_ADVFEATURE_NO_INIT;
  if (HAL_HalfDuplex_Init(&huart2) != HAL_OK)
  {
    Error_Handler();
  }
  if (HAL_UARTEx_SetTxFifoThreshold(&huart2, UART_TXFIFO_THRESHOLD_1_8) != HAL_OK)
  {
    Error_Handler();
  }
  if (HAL_UARTEx_SetRxFifoThreshold(&huart2, UART_RXFIFO_THRESHOLD_1_8) != HAL_OK)
  {
    Error_Handler();
  }
  if (HAL_UARTEx_DisableFifoMode(&huart2) != HAL_OK)
  {
    Error_Handler();
  }

}

static void MX_DMA_Init(void)
{

  /* DMA controller clock enable */
  __HAL_RCC_DMAMUX1_CLK_ENABLE();
  __HAL_RCC_DMA1_CLK_ENABLE();
  __HAL_RCC_DMA2_CLK_ENABLE();

  /* DMA interrupt init */
  /* DMA1_Channel1_IRQn interrupt configuration */
  HAL_NVIC_SetPriority(DMA1_Channel1_IRQn, 0, 0);
  HAL_NVIC_EnableIRQ(DMA1_Channel1_IRQn);
  /* DMA1_Channel3_IRQn interrupt configuration */
  HAL_NVIC_SetPriority(DMA1_Channel3_IRQn, 0, 0);
  HAL_NVIC_EnableIRQ(DMA1_Channel3_IRQn);
  /* DMA1_Channel4_IRQn interrupt configuration */
  HAL_NVIC_SetPriority(DMA1_Channel4_IRQn, 0, 0);
  HAL_NVIC_EnableIRQ(DMA1_Channel4_IRQn);
  /* DMA2_Channel1_IRQn interrupt configuration */
  HAL_NVIC_SetPriority(DMA2_Channel1_IRQn, 0, 0);
  HAL_NVIC_EnableIRQ(DMA2_Channel1_IRQn);
  /* DMA2_Channel2_IRQn interrupt configuration */
  HAL_NVIC_SetPriority(DMA2_Channel2_IRQn, 0, 0);
  HAL_NVIC_EnableIRQ(DMA2_Channel2_IRQn);

}

static void MX_GPIO_Init(void)
{
  GPIO_InitTypeDef GPIO_InitStruct = {0};

  /* GPIO Ports Clock Enable */
  __HAL_RCC_GPIOC_CLK_ENABLE();
  __HAL_RCC_GPIOF_CLK_ENABLE();
  __HAL_RCC_GPIOA_CLK_ENABLE();
  __HAL_RCC_GPIOB_CLK_ENABLE();

  /*Configure GPIO pin Output Level */
  HAL_GPIO_WritePin(TEST_LED_GPIO_Port, TEST_LED_Pin, GPIO_PIN_RESET);

  /*Configure GPIO pin Output Level */
  HAL_GPIO_WritePin(GPIOB, TFT_A0_Pin|TFT_RESET_Pin|TFT_CS_Pin, GPIO_PIN_RESET);

  /*Configure GPIO pin : TEST_LED_Pin */
  GPIO_InitStruct.Pin = TEST_LED_Pin;
  GPIO_InitStruct.Mode = GPIO_MODE_OUTPUT_PP;
  GPIO_InitStruct.Pull = GPIO_NOPULL;
  GPIO_InitStruct.Speed = GPIO_SPEED_FREQ_LOW;
  HAL_GPIO_Init(TEST_LED_GPIO_Port, &GPIO_InitStruct);

  /*Configure GPIO pins : TFT_A0_Pin TFT_RESET_Pin TFT_CS_Pin */
  GPIO_InitStruct.Pin = TFT_A0_Pin|TFT_RESET_Pin|TFT_CS_Pin;
  GPIO_InitStruct.Mode = GPIO_MODE_OUTPUT_PP;
  GPIO_InitStruct.Pull = GPIO_NOPULL;
  GPIO_InitStruct.Speed = GPIO_SPEED_FREQ_LOW;
  HAL_GPIO_Init(GPIOB, &GPIO_InitStruct);

  /*Configure GPIO pins : USB_ALERT_Pin PG_1V8_Pin PG_3V3_Pin */
  GPIO_InitStruct.Pin = USB_ALERT_Pin|PG_1V8_Pin|PG_3V3_Pin;
  GPIO_InitStruct.Mode = GPIO_MODE_INPUT;
  GPIO_InitStruct.Pull = GPIO_NOPULL;
  HAL_GPIO_Init(GPIOB, &GPIO_InitStruct);

}

void Error_Handler(void)
{
  __disable_irq();
  while (1)
  {
  }
}
